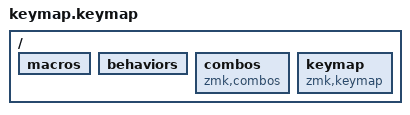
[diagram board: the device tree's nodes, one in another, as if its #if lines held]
/*
 * Copyright (c) 2024 The ZMK Contributors
 *
 * SPDX-License-Identifier: MIT
 */

#include <behaviors.dtsi>
#include <behaviors/mouse_keys.dtsi>
#include <dt-bindings/zmk/keys.h>
#include <dt-bindings/zmk/bt.h>
#include <dt-bindings/zmk/rgb.h>
#include <dt-bindings/zmk/pointing.h>
#include <dt-bindings/zmk/ext_power.h>

// HELPERS
#include "positions.keymap"
#include "helpers/timings.keymap"
#include "helpers/combos_include.keymap"
#include "helpers/macros_include.keymap"
#include "helpers/press.keymap"

// LAYERS
#ifndef BASE
#include "helpers/layers.keymap"
#endif

// KEYS
#include "helpers/keys.keymap"

/ {
    macros {
        #include "helpers/macros.keymap"
    };

    behaviors {
        #include "helpers/tap_dance.keymap"
    };

    combos {
        compatible = "zmk,combos";
        #include "helpers/combos.keymap"
    };

    keymap {
        compatible = "zmk,keymap";

            #include "keymaps/0.base.keymap"
            #include "keymaps/1.nav.keymap"
            #include "keymaps/2.functions.keymap"
            #include "keymaps/3.symbols_kp.keymap"
            #include "keymaps/4.utils.keymap"
            #include "keymaps/5.mirror.keymap"
            #include "keymaps/6.combos.keymap"
    };
};

#ifdef KAIROS_TRACKPAD_NAV
#include "helpers/pointer-speeds.keymap"
#endif
